# R7FA8M1AH register map
Vendor: Renesas; Series: RA8; File version: 1.2
CPU: CM85 r0p0, little endian, MPU, FPU, VTOR, 4 interrupt priority bits
Registers are 32-bit, read-write, reset 0x0 unless marked. A register's access mark holds for its fields unless they carry their own. Offsets are from the block's base; [hi:lo] are bit positions; 'fields as' and 'values as' point back to an identical list.

## ECCMB0 — Error correction circuit for MBRAM0
Base 0x4036F200
Same registers: ECCMB1 0x4036F300, ECCMB0_NS 0x5036F200, ECCMB1_NS 0x5036F300
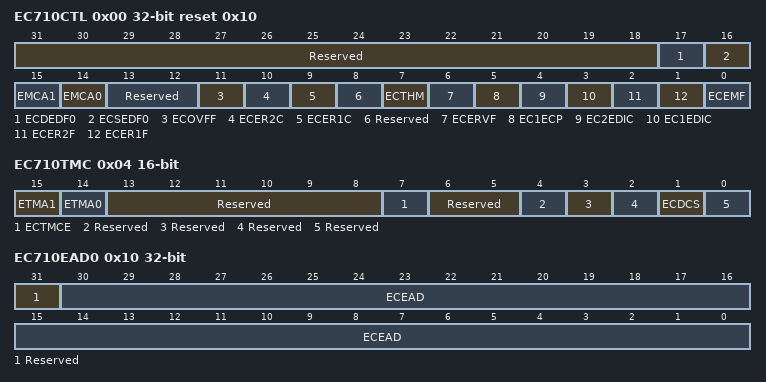
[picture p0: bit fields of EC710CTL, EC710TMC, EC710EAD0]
0x00 EC710CTL reset 0x10 — ECC control register
  [31:18] Reserved — These bits are read as 00000000000000. The write value should be 00000000000000.
  [17] ECDEDF0 ro — Flag bit of ECC Dual bit Error Detection
    0=no bit error; 1=2bits error occurred
  [16] ECSEDF0 ro — Flag bit of ECC Single bit Error Detection
    0=no bit error; 1=1bits error occurred
  [15] EMCA1 — Access control bit1 to ECC mode select bit
  [14] EMCA0 — Access control bit0 to ECC mode select bit
  [13:12] Reserved — These bits are read as 00. The write value should be 00.
  [11] ECOVFF ro — Flag bit of ECC overflow detection
    0=Overflow is not occurred after reset or clearing ECER2F and ECER1F; 1=Error address register overflowed
  [10] ECER2C — Flag clear bit of 2bits ECC error detection
  [9] ECER1C — Flag clear bit of accumulating ECC error detection and correction
  [8] Reserved — This bit is read as 0. The write value should be 0.
  [7] ECTHM — Select bit of ECC function through mode
    0=Through mode disable (normal operation mode). Initial value.; 1=Through mode enable
  [6] ECERVF — Flag bit to enable ECC error judgment
  [5] EC1ECP — Permission bit of ECC 1bit error correction
  [4] EC2EDIC — Control bit of interrupt at ECC 2bits error detection
    0=Interrupt is not occurred at detecting 2bits error; 1=EC7TIE2 is outputted at detecting 2bits error. (initial value)
  [3] EC1EDIC — Control bit of interrupt at ECC 1bit error detection
    0=Interrupt is not occurred at detecting 2bit error; 1=EC7TIE2 is outputted at detecting 1bit error
  [2] ECER2F ro — Flag bit of 2bits ECC error detection
  [1] ECER1F ro — Flag bit of ECC error detection and correction
  [0] ECEMF ro — Flag bit of ECC error message
0x04 EC710TMC 16-bit — ECC test mode control register
  [15] ETMA1 — Access control bit1 and bit0 to ECC test mode bit
  [14] ETMA0 — Access control bit1 and bit0 to ECC test mode bit
  [13:8] Reserved — These bits are read as 000000. The write value should be 000000.
  [7] ECTMCE — Enable bit of ECC test mode control
  [6:5] Reserved — These bits are read as 00. The write value should be 00.
  [4] Reserved — This bit is read as 0. The write value should be 0.
  [3] Reserved — This bit is read as 0. The write value should be 0.
  [2] Reserved — This bit is read as 0. The write value should be 0.
  [1] ECDCS — Select bit of ECC decode input
  [0] Reserved — This bit is read as 0. The write value should be 0.
0x0C EC710TED — ECC encode or decode data test register
  [31:0] ECEDB — At test mode, this register data is used as input data to encode circuit or decode circuit
0x10 EC710EAD0 ro — ECC error address register0
  [31] Reserved — This bit is read as 0.
  [30:0] ECEAD — This is read only register to hold the ECC error occurred address.

## PORT0 — Port 0 Control Registers
Base 0x40400000
Same registers: PORT5 0x404000A0, PORT6 0x404000C0, PORT7 0x404000E0, PORT8 0x40400100, PORT9 0x40400120, PORTA 0x40400140, PORTB 0x40400160, PORTC 0x40400180, PORTD 0x404001A0, PORTE 0x404001C0, PORTF 0x404001E0, PORTG 0x40400200, PORT0_NS 0x50400000, PORT5_NS 0x504000A0, PORT6_NS 0x504000C0, PORT7_NS 0x504000E0, PORT8_NS 0x50400100, PORT9_NS 0x50400120, PORTA_NS 0x50400140, PORTB_NS 0x50400160, PORTC_NS 0x50400180, PORTD_NS 0x504001A0, PORTE_NS 0x504001C0, PORTF_NS 0x504001E0, PORTG_NS 0x50400200
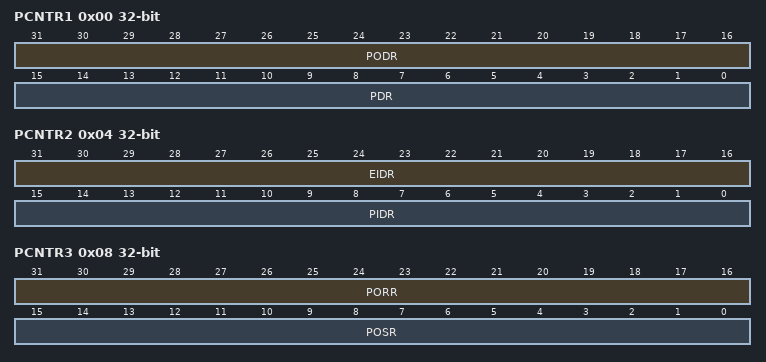
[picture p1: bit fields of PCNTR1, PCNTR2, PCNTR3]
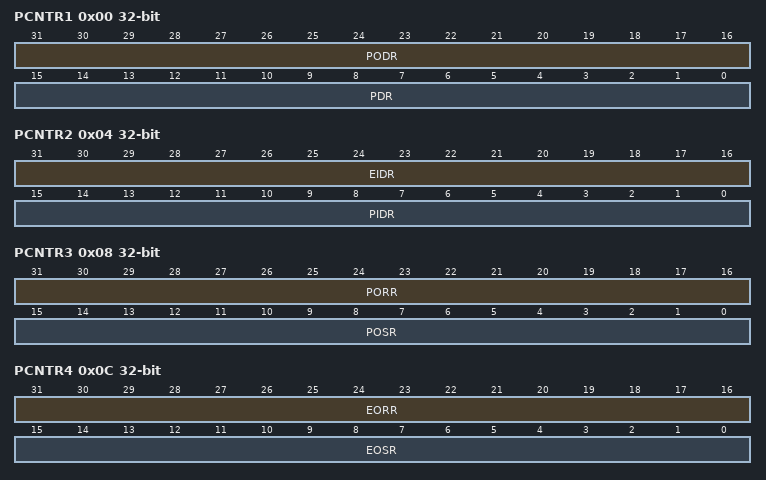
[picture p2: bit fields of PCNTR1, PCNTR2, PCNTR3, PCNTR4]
0x00 PCNTR1 — Port Control Register 1
  [31:16] PODR — Pmn Output Data
    0=Low output; 1=High output
  [15:0] PDR — Pmn Direction
    0=Input (functions as an input pin); 1=Output (functions as an output pin)
0x00 PDR 16-bit (alternate view of PCNTR1) — Data direction register
  [15:0] PDR — Pmn Direction
    values as PCNTR1.PDR
0x02 PODR 16-bit (alternate view of PCNTR1) — Output data register
  [15:0] PODR — Pmn Output Data
    0=Low output; 1=High output
0x04 PCNTR2 ro (reset mask 0xFFFF0000) — Port Control Register 2
  [31:16] EIDR — Pmn Event Input Data
    0=Low input; 1=High input
  [15:0] PIDR — Pmn Input Data
    0=Low input; 1=High input
0x04 PIDR 16-bit ro reset not defined (alternate view of PCNTR2) — Input data register
  [15:0] PIDR — Pmn Input Data
    0=Low level; 1=high level
0x06 EIDR 16-bit ro reset not defined (alternate view of PCNTR2) — Port Event Input Data register
  [15:0] EIDR — Port Event Input Data
    0=Low input; 1=High input
0x08 PCNTR3 wo — Port Control Register 3
  [31:16] PORR — Pmn Output Reset
    0=No affect to output; 1=Low output
  [15:0] POSR — Pmn Output Set
    0=No affect to output; 1=High output
0x08 POSR 16-bit wo (alternate view of PCNTR3) — Output set register
  [15:0] POSR — Pmn Output Set
    0=No affect to output; 1=High output
0x0A PORR 16-bit wo (alternate view of PCNTR3) — Output reset register
  [15:0] PORR — Pmn Output Reset
    0=No affect to output; 1=Low output

## PORT1 — Port 1 Control Registers
Base 0x40400020
Same registers: PORT2 0x40400040, PORT3 0x40400060, PORT4 0x40400080, PORT1_NS 0x50400020, PORT2_NS 0x50400040, PORT3_NS 0x50400060, PORT4_NS 0x50400080
0x00 PCNTR1 — Port Control Register 1
  [31:16] PODR — Pmn Output Data
    0=Low output; 1=High output
  [15:0] PDR — Pmn Direction
    0=Input (functions as an input pin); 1=Output (functions as an output pin)
0x00 PDR 16-bit (alternate view of PCNTR1) — Data direction register
  [15:0] PDR — Pmn Direction
    values as PCNTR1.PDR
0x02 PODR 16-bit (alternate view of PCNTR1) — Output data register
  [15:0] PODR — Pmn Output Data
    0=Low output; 1=High output
0x04 PCNTR2 ro (reset mask 0xFFFF0000) — Port Control Register 2
  [31:16] EIDR — Pmn Event Input Data
    0=Low input; 1=High input
  [15:0] PIDR — Pmn Input Data
    0=Low input; 1=High input
0x04 PIDR 16-bit ro reset not defined (alternate view of PCNTR2) — Input data register
  [15:0] PIDR — Pmn Input Data
    0=Low input; 1=High input
0x06 EIDR 16-bit ro reset not defined (alternate view of PCNTR2) — Event input data register
  [15:0] EIDR — Pmn Event Input Data
    0=Low input; 1=High input
0x08 PCNTR3 wo — Port Control Register 3
  [31:16] PORR — Pmn Output Reset
    0=No affect to output; 1=Low output
  [15:0] POSR — Pmn Output Set
    0=No affect to output; 1=High output
0x08 POSR 16-bit wo (alternate view of PCNTR3) — Output reset register
  [15:0] POSR — Pmn Output Set
    0=No affect to output; 1=High output
0x0A PORR 16-bit wo (alternate view of PCNTR3) — Output set register
  [15:0] PORR — Pmn Output Reset
    0=No affect to output; 1=Low output
0x0C PCNTR4 — Port Control Register 4
  [31:16] EORR — Pmn Event Output Reset
    0=No affect to output; 1=Low output
  [15:0] EOSR — Pmn Event Output Set
    0=No affect to output; 1=High output
0x0C EOSR 16-bit (alternate view of PCNTR4) — Event output reset register
  [15:0] EOSR — Pmn Event Output Set
    0=No affect to output; 1=High output
0x0E EORR 16-bit (alternate view of PCNTR4) — Event output set register
  [15:0] EORR — Pmn Event Output Reset
    0=No affect to output; 1=Low output
